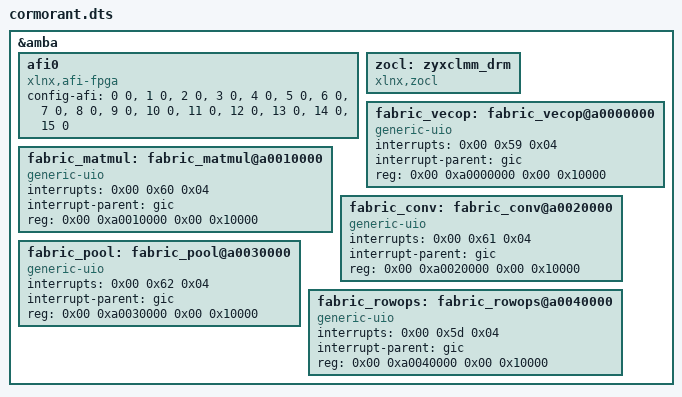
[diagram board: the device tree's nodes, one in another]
/*
 * CAUTION: This file is automatically generated by Xilinx.
 * Version: XSCT 2025.2
 * Today is: Thu Apr 23 02:18:38 2026
 */


/dts-v1/;
/plugin/;
/ {
	/*afi*/
	/*TODO is afi necessary?*/
	fragment@1 {
		target = <&amba>;
		overlay1: __overlay__ {
			afi0: afi0 {
				compatible = "xlnx,afi-fpga";
				config-afi = <0 0>, <1 0>, <2 0>, <3 0>, <4 0>, <5 0>, <6 0>,
							 <7 0>, <8 0>, <9 0>, <10 0>, <11 0>, <12 0>, 
							 <13 0>, <14 0>, <15 0>;
			};
		};
	};

	/* zocl */
	fragment@2 {
		target = <&amba>;
		overlay2: __overlay__ {
			zocl: zyxclmm_drm {
				compatible = "xlnx,zocl";
				status = "okay";
			};
		};
	};

	/*uio*/
	fragment@3 {
		target = <&amba>;
		overlay3: __overlay__ {
			fabric_vecop: fabric_vecop@a0000000 {
				interrupts = <0x00 0x59 0x04>;
				interrupt-parent = <&gic>;
				compatible = "generic-uio";
				reg = <0x00 0xa0000000 0x00 0x10000>;
			};
		};
	};

	/*uio*/
	fragment@4 {
		target = <&amba>;
		overlay4: __overlay__ {
			fabric_matmul: fabric_matmul@a0010000 {
				interrupts = <0x00 0x60 0x04>;
				interrupt-parent = <&gic>;
				compatible = "generic-uio";
				reg = <0x00 0xa0010000 0x00 0x10000>;
			};
		};
	};

	/*uio*/
	fragment@5 {
		target = <&amba>;
		overlay5: __overlay__ {
			fabric_conv: fabric_conv@a0020000 {
				interrupts = <0x00 0x61 0x04>;
				interrupt-parent = <&gic>;
				compatible = "generic-uio";
				reg = <0x00 0xa0020000 0x00 0x10000>;
			};
		};
	};

	/*uio*/
	fragment@6 {
		target = <&amba>;
		overlay6: __overlay__ {
			fabric_pool: fabric_pool@a0030000 {
				interrupts = <0x00 0x62 0x04>;
				interrupt-parent = <&gic>;
				compatible = "generic-uio";
				reg = <0x00 0xa0030000 0x00 0x10000>;
			};
		};
	};

	/*uio: the row-ops unit (RowOpsKernel, pl_ps_irq0[4] = SPI 125)*/
	fragment@7 {
		target = <&amba>;
		overlay7: __overlay__ {
			fabric_rowops: fabric_rowops@a0040000 {
				interrupts = <0x00 0x5d 0x04>;
				interrupt-parent = <&gic>;
				compatible = "generic-uio";
				reg = <0x00 0xa0040000 0x00 0x10000>;
			};
		};
	};
};
